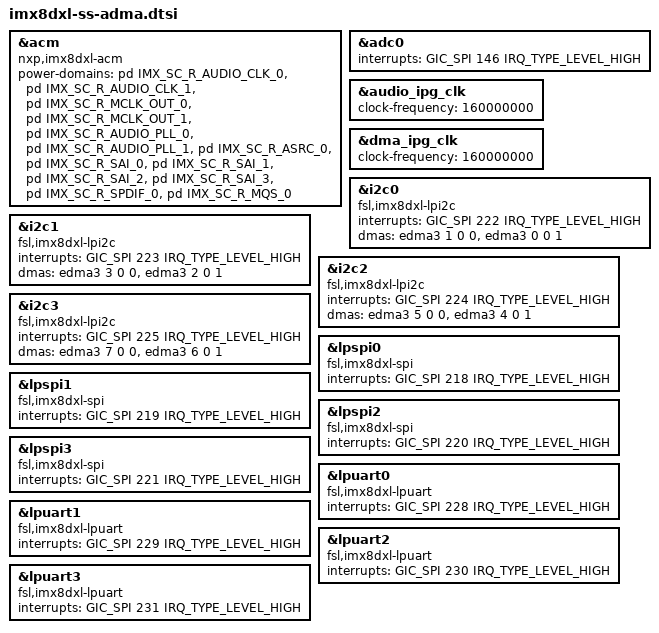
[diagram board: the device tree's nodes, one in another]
// SPDX-License-Identifier: GPL-2.0+
/*
 * Copyright 2019~2020, 2022 NXP
 */

/delete-node/ &asrc1;
/delete-node/ &asrc1_lpcg;
/delete-node/ &adc1;
/delete-node/ &adc1_lpcg;
/delete-node/ &amix;
/delete-node/ &amix_lpcg;
/delete-node/ &dsp_lpcg;
/delete-node/ &dsp_ram_lpcg;
/delete-node/ &edma1;
/delete-node/ &emvsim0;
/delete-node/ &emvsim0_lpcg;
/delete-node/ &esai0;
/delete-node/ &esai0_lpcg;
/delete-node/ &sai4;
/delete-node/ &sai4_lpcg;
/delete-node/ &sai5;
/delete-node/ &sai5_lpcg;
/delete-node/ &spdif1;
/delete-node/ &spdif1_lpcg;

&acm {
	compatible = "nxp,imx8dxl-acm";
	power-domains = <&pd IMX_SC_R_AUDIO_CLK_0>,
			<&pd IMX_SC_R_AUDIO_CLK_1>,
			<&pd IMX_SC_R_MCLK_OUT_0>,
			<&pd IMX_SC_R_MCLK_OUT_1>,
			<&pd IMX_SC_R_AUDIO_PLL_0>,
			<&pd IMX_SC_R_AUDIO_PLL_1>,
			<&pd IMX_SC_R_ASRC_0>,
			<&pd IMX_SC_R_SAI_0>,
			<&pd IMX_SC_R_SAI_1>,
			<&pd IMX_SC_R_SAI_2>,
			<&pd IMX_SC_R_SAI_3>,
			<&pd IMX_SC_R_SPDIF_0>,
			<&pd IMX_SC_R_MQS_0>;
};

&adc0 {
	interrupts = <GIC_SPI 146 IRQ_TYPE_LEVEL_HIGH>;
};

&audio_ipg_clk {
	clock-frequency = <160000000>;
};

&dma_ipg_clk {
	clock-frequency = <160000000>;
};

&adc0 {
	interrupts = <GIC_SPI 146 IRQ_TYPE_LEVEL_HIGH>;
};

&i2c0 {
	compatible = "fsl,imx8dxl-lpi2c", "fsl,imx8qxp-lpi2c", "fsl,imx7ulp-lpi2c";
	interrupts = <GIC_SPI 222 IRQ_TYPE_LEVEL_HIGH>;
	dma-names = "tx","rx";
	dmas = <&edma3 1 0 0>, <&edma3 0 0 1>;
};

&i2c1 {
	compatible = "fsl,imx8dxl-lpi2c", "fsl,imx8qxp-lpi2c", "fsl,imx7ulp-lpi2c";
	interrupts = <GIC_SPI 223 IRQ_TYPE_LEVEL_HIGH>;
	dma-names = "tx","rx";
	dmas = <&edma3 3 0 0>, <&edma3 2 0 1>;
};

&i2c2 {
	compatible = "fsl,imx8dxl-lpi2c", "fsl,imx8qxp-lpi2c", "fsl,imx7ulp-lpi2c";
	interrupts = <GIC_SPI 224 IRQ_TYPE_LEVEL_HIGH>;
	dma-names = "tx","rx";
	dmas = <&edma3 5 0 0>, <&edma3 4 0 1>;
};

&i2c3 {
	compatible = "fsl,imx8dxl-lpi2c", "fsl,imx8qxp-lpi2c", "fsl,imx7ulp-lpi2c";
	interrupts = <GIC_SPI 225 IRQ_TYPE_LEVEL_HIGH>;
	dma-names = "tx","rx";
	dmas = <&edma3 7 0 0>, <&edma3 6 0 1>;
};

&lpspi0 {
	compatible = "fsl,imx8dxl-spi", "fsl,imx8qxp-spi", "fsl,imx7ulp-spi";
	interrupts = <GIC_SPI 218 IRQ_TYPE_LEVEL_HIGH>;
};

&lpspi1 {
	compatible = "fsl,imx8dxl-spi", "fsl,imx8qxp-spi", "fsl,imx7ulp-spi";
	interrupts = <GIC_SPI 219 IRQ_TYPE_LEVEL_HIGH>;
};

&lpspi2 {
	compatible = "fsl,imx8dxl-spi", "fsl,imx8qxp-spi", "fsl,imx7ulp-spi";
	interrupts = <GIC_SPI 220 IRQ_TYPE_LEVEL_HIGH>;
};

&lpspi3 {
	compatible = "fsl,imx8dxl-spi", "fsl,imx8qxp-spi", "fsl,imx7ulp-spi";
	interrupts = <GIC_SPI 221 IRQ_TYPE_LEVEL_HIGH>;
};

&lpuart0 {
	compatible = "fsl,imx8dxl-lpuart", "fsl,imx8qxp-lpuart";
	interrupts = <GIC_SPI 228 IRQ_TYPE_LEVEL_HIGH>;
};

&lpuart1 {
	compatible = "fsl,imx8dxl-lpuart", "fsl,imx8qxp-lpuart";
	interrupts = <GIC_SPI 229 IRQ_TYPE_LEVEL_HIGH>;
};

&lpuart2 {
	compatible = "fsl,imx8dxl-lpuart", "fsl,imx8qxp-lpuart";
	interrupts = <GIC_SPI 230 IRQ_TYPE_LEVEL_HIGH>;
};

&lpuart3 {
	compatible = "fsl,imx8dxl-lpuart", "fsl,imx8qxp-lpuart";
	interrupts = <GIC_SPI 231 IRQ_TYPE_LEVEL_HIGH>;
};

&lpspi0 {
	interrupts = <GIC_SPI 218 IRQ_TYPE_LEVEL_HIGH>;
};

&lpspi1 {
	interrupts = <GIC_SPI 219 IRQ_TYPE_LEVEL_HIGH>;
};

&lpspi2 {
	interrupts = <GIC_SPI 220 IRQ_TYPE_LEVEL_HIGH>;
};

&lpspi3 {
	interrupts = <GIC_SPI 221 IRQ_TYPE_LEVEL_HIGH>;
};
